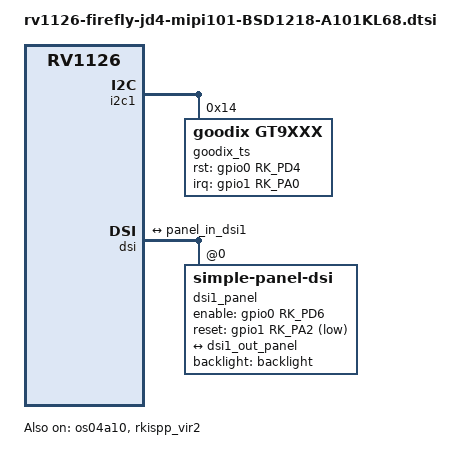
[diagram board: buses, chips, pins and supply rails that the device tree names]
// SPDX-License-Identifier: (GPL-2.0+ OR MIT)
/*
 * Copyright (c) 2020 Rockchip Electronics Co., Ltd.
 */

#include "rv1126-firefly-jd4.dtsi"

&gsl3680 {
	status = "disabled";
};

&os04a10 {
	status = "okay";
};

&lcd_n {
	status = "disabled";
};

&i2c1 {
	status = "okay";

	goodix_ts: goodix-tx@14 {
                status = "okay";
                compatible = "goodix,gt9xxx";
                reg = <0x14>;
		interrupt-parent = <&gpio1>;
		interrupts = <RK_PA0 IRQ_TYPE_LEVEL_LOW>;
                goodix,rst-gpio = <&gpio0 RK_PD4 GPIO_ACTIVE_HIGH>;
                goodix,irq-gpio = <&gpio1 RK_PA0 IRQ_TYPE_LEVEL_LOW>;

                flip-x = <1>;
                flip-y = <1>;
                touchscreen-swapped-x-y;
 
                goodix,cfg-group2 = [
                        5E 20 03 00 05 0A 35 00 01 0A 28 
                        0F 50 3C 03 05 00 00 00 00 00 00 
                        06 18 1A 1E 14 90 30 AA 37 39 12 
                        0C 00 00 00 1A 02 2D 00 00 00 00 
                        00 00 00 00 07 00 00 28 4B 94 D5 
                        02 07 00 00 04 9A 2A 00 8C 30 00 
                        81 36 00 76 3E 00 6E 46 00 6E 00 
                        00 00 00 00 00 00 00 00 00 00 00 
                        00 00 00 00 00 00 00 00 00 00 00 
                        00 00 00 00 00 02 00 00 00 00 00 
                        00 00 00 01 04 05 06 07 08 09 0C 
                        0D 0E 0F 10 11 14 15 16 17 18 19 
                        00 00 00 00 00 00 00 00 00 00 2A 
                        29 28 27 26 25 24 23 22 21 20 1F 
                        1E 1C 1B 19 00 02 04 06 07 08 0A 
                        0C 0D 0E 0F 10 11 12 13 14 00 00 
                        00 00 00 00 00 00 00 00 DC 01];
	};
};

&dsi {
	status = "okay";
	dsi1_panel: panel@0 {
		status = "okay";
		compatible = "simple-panel-dsi";
		reg = <0>;
		backlight = <&backlight>;
		
                /delete-property/ power-supply;
		enable-gpios = <&gpio0 RK_PD6 GPIO_ACTIVE_HIGH>;
		reset-gpios = <&gpio1 RK_PA2 GPIO_ACTIVE_LOW>;

		pinctrl-0 = <&lcd_ctl>,<&lcd_rst>;
                pinctrl-names = "default";

		enable-delay-ms = <50>;
		prepare-delay-ms = <200>;
		reset-delay-ms = <50>;
		init-delay-ms = <55>;
		unprepare-delay-ms = <50>;
		disable-delay-ms = <20>;
		mipi-data-delay-ms = <200>;
		size,width = <120>;
		size,height = <170>;
		dsi,flags = <(MIPI_DSI_MODE_VIDEO | MIPI_DSI_MODE_VIDEO_BURST | MIPI_DSI_MODE_LPM | MIPI_DSI_MODE_EOT_PACKET)>;
		dsi,format = <MIPI_DSI_FMT_RGB888>;
		dsi,lanes  = <4>;

		panel-init-sequence = [
			39 00 04 FF 98 81 03
			15 00 02 01 00
			15 00 02 02 00
			15 00 02 03 55
			15 00 02 04 55
			15 00 02 05 03 
			15 00 02 06 06 
			15 00 02 07 00 
			15 00 02 08 07 
			15 00 02 09 00 
			15 00 02 0a 00 
			15 00 02 0b 00 
			15 00 02 0c 00 
			15 00 02 0d 00 
			15 00 02 0e 00 
			15 00 02 0f 00 

			15 00 02 10 00 
			15 00 02 11 00 
			15 00 02 12 00
			15 00 02 13 00
			15 00 02 14 00
			15 00 02 15 00
			15 00 02 16 00
			15 00 02 17 00
			15 00 02 18 00
			15 00 02 19 00
			15 00 02 1a 00
			15 00 02 1b 00
			15 00 02 1c 00
			15 00 02 1d 00
			15 00 02 1e C0
			15 00 02 1f 80

			15 00 02 20 04
			15 00 02 21 03
			15 00 02 22 00
			15 00 02 23 00
                        15 00 02 24 00
			15 00 02 25 00
			15 00 02 26 00
			15 00 02 27 00
			15 00 02 28 33
			15 00 02 29 33
			15 00 02 2a 00
			15 00 02 2b 00
			15 00 02 2c 00
			15 00 02 2d 00
			15 00 02 2e 00
			15 00 02 2f 00

			15 00 02 30 00
			15 00 02 31 00
			15 00 02 32 00
			15 00 02 33 00
			15 00 02 34 04
			15 00 02 35 00
			15 00 02 36 00
			15 00 02 37 00
			15 00 02 38 3C
                        15 00 02 39 00
			15 00 02 3a 00
			15 00 02 3b 00
			15 00 02 3c 00
			15 00 02 3d 00
			15 00 02 3e 00
			15 00 02 3f 00

			15 00 02 40 00
			15 00 02 41 00
			15 00 02 42 00
			15 00 02 43 00
			15 00 02 44 00

			15 00 02 50 00
			15 00 02 51 11
			15 00 02 52 44
			15 00 02 53 55
			15 00 02 54 88
			15 00 02 55 AB
			15 00 02 56 00
			15 00 02 57 11
                        15 00 02 58 22
			15 00 02 59 33
			15 00 02 5a 44
			15 00 02 5b 55
			15 00 02 5c 66
			15 00 02 5d 77
			15 00 02 5e 00
			15 00 02 5f 02

			15 00 02 60 02
			15 00 02 61 0A
			15 00 02 62 09
			15 00 02 63 08
			15 00 02 64 13
			15 00 02 65 12
			15 00 02 66 11
			15 00 02 67 10
			15 00 02 68 0F
			15 00 02 69 0E
			15 00 02 6a 0D
			15 00 02 6b 0C
			15 00 02 6c 06
                        15 00 02 6d 07
			15 00 02 6e 02  
			15 00 02 6f 02

			15 00 02 70 02
			15 00 02 71 02
			15 00 02 72 02
			15 00 02 73 02 
			15 00 02 74 02
			15 00 02 75 02
			15 00 02 76 02  
			15 00 02 77 0A
			15 00 02 78 06
			15 00 02 79 07
			15 00 02 7a 10
			15 00 02 7b 11
			15 00 02 7c 12
			15 00 02 7d 13
			15 00 02 7e 0C
			15 00 02 7f 0D

			15 00 02 80 0E
                        15 00 02 81 0F
			15 00 02 82 09
			15 00 02 83 08
			15 00 02 84 02
			15 00 02 85 02
			15 00 02 86 02
			15 00 02 87 02
			15 00 02 88 02
			15 00 02 89 02
			15 00 02 8A 02

			39 00 04 FF 98 81 04
			15 00 02 6E 2A
			15 00 02 6F 37
			15 00 02 3A 24
			15 00 02 8D 19
			15 00 02 87 BA
			15 00 02 B2 D1
			15 00 02 88 0B
			15 00 02 38 01
			15 00 02 39 00
			15 00 02 B5 02
                        15 00 02 31 25
			15 00 02 3B 98
			39 00 04 FF 98 81 01

			15 00 02 22 0A
			15 00 02 31 0C
			15 00 02 53 40
			15 00 02 55 45
			15 00 02 50 B7
			15 00 02 51 B2
			15 00 02 60 07

			15 00 02 A0 22
			15 00 02 A1 3F
			15 00 02 A2 4E
			15 00 02 A3 17
			15 00 02 A4 1A
			15 00 02 A5 2D
			15 00 02 A6 21
			15 00 02 A7 22
			15 00 02 A8 C4
			15 00 02 A9 1B
                        15 00 02 AA 25
			15 00 02 AB A7
			15 00 02 AC 1A
			15 00 02 AD 19
			15 00 02 AE 4B
			15 00 02 AF 1F

			15 00 02 B0 2A
			15 00 02 B1 59
			15 00 02 B2 64
			15 00 02 B3 3F

			15 00 02 C0 22
			15 00 02 C1 48
			15 00 02 C2 59
			15 00 02 C3 15
			15 00 02 C4 15
			15 00 02 C5 28
			15 00 02 C6 1C
			15 00 02 C7 1E
			15 00 02 C8 C4
			15 00 02 C9 1C
			15 00 02 CA 2B
                        15 00 02 CB A3
			15 00 02 CC 1F
			15 00 02 CD 1E
			15 00 02 CE 52
			15 00 02 CF 24

			15 00 02 D0 2A
			15 00 02 D1 58
			15 00 02 D2 68
			15 00 02 D3 3F      
			39 00 04 FF 98 81 00
			05 78 01 11             //Delay 120ms
			05 14 01 29             //Delay 20ms
		];

		panel-exit-sequence = [
			39 00 04 FF 98 81 00        //page0
			05 14 01 28                //Delay 20ms
			05 78 01 10                //Delay 120ms
		];

		dis1_timings0: display-timings {
			native-mode = <&dsi1_timing0>;
			dsi1_timing0: timing0 {
				clock-frequency = <70000000>;//<80000000>;
				hactive = <800>;//<768>;
				vactive = <1280>;
				hsync-len = <20>;   //20, 50,10
				hback-porch = <20>; //50, 56,10
				hfront-porch = <40>;//50, 30,180
				vsync-len = <4>;//4
				vback-porch = <20>;//4
				vfront-porch = <20>;//8
				hsync-active = <0>;
				vsync-active = <0>;
				de-active = <0>;
				pixelclk-active = <0>;
			};
		};

		ports {
			#address-cells = <1>;
			#size-cells = <0>;

			port@0 {
				reg = <0>;
				panel_in_dsi1: endpoint {
					remote-endpoint = <&dsi1_out_panel>;
				};
			};
		};
	};

	ports {
		#address-cells = <1>;
		#size-cells = <0>;

		port@1 {
			reg = <1>;
			dsi1_out_panel: endpoint {
			remote-endpoint = <&panel_in_dsi1>;
			};
		};
	};
};

&rkispp_vir2 {
	status = "okay";
};
